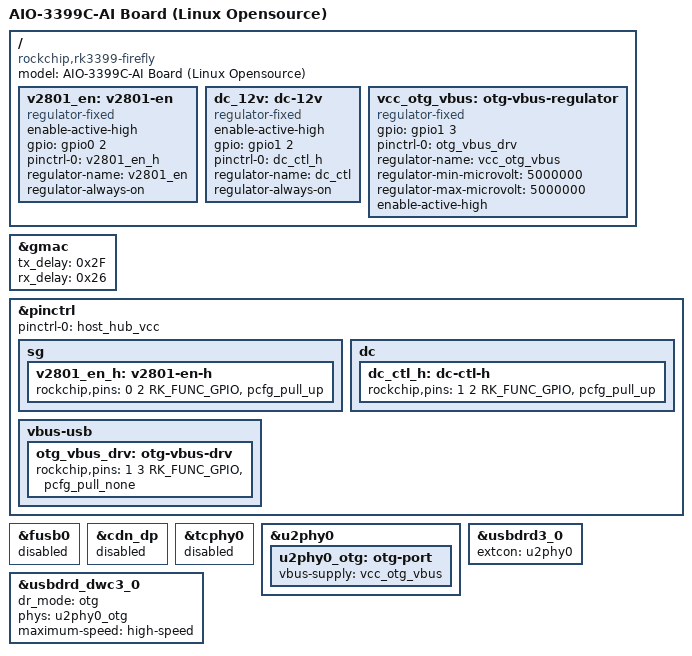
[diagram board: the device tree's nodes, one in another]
/*
 * Copyright (c) 2016 Fuzhou Rockchip Electronics Co., Ltd
 *
 * This file is dual-licensed: you can use it either under the terms
 * of the GPL or the X11 license, at your option. Note that this dual
 * licensing only applies to this file, and not this project as a
 * whole.
 *
 *  a) This file is free software; you can redistribute it and/or
 *     modify it under the terms of the GNU General Public License as
 *     published by the Free Software Foundation; either version 2 of the
 *     License, or (at your option) any later version.
 *
 *     This file is distributed in the hope that it will be useful,
 *     but WITHOUT ANY WARRANTY; without even the implied warranty of
 *     MERCHANTABILITY or FITNESS FOR A PARTICULAR PURPOSE.  See the
 *     GNU General Public License for more details.
 *
 * Or, alternatively,
 *     restriction, including without limitation the rights to use,
 *     copy, modify, merge, publish, distribute, sublicense, and/or
 *     sell copies of the Software, and to permit persons to whom the
 *     Software is furnished to do so, subject to the following
 *     conditions:
 *
 *     The above copyright notice and this permission notice shall be
 *     included in all copies or substantial portions of the Software.
 *
 *     THE SOFTWARE IS PROVIDED "AS IS", WITHOUT WARRANTY OF ANY KIND,
 *     EXPRESS OR IMPLIED, INCLUDING BUT NOT LIMITED TO THE WARRANTIES
 *     OF MERCHANTABILITY, FITNESS FOR A PARTICULAR PURPOSE AND
 *     NONINFRINGEMENT. IN NO EVENT SHALL THE AUTHORS OR COPYRIGHT
 *     HOLDERS BE LIABLE FOR ANY CLAIM, DAMAGES OR OTHER LIABILITY,
 *     WHETHER IN AN ACTION OF CONTRACT, TORT OR OTHERWISE, ARISING
 *     FROM, OUT OF OR IN CONNECTION WITH THE SOFTWARE OR THE USE OR
 *     OTHER DEALINGS IN THE SOFTWARE.
 */

/dts-v1/;

#include "rk3399-firefly-aioc.dtsi"

/ {
	model = "AIO-3399C-AI Board (Linux Opensource)";
	compatible = "rockchip,rk3399-firefly", "rockchip,rk3399";

	v2801_en: v2801-en {
		compatible = "regulator-fixed";
		enable-active-high;
		gpio = <&gpio0 2 GPIO_ACTIVE_HIGH>;
		pinctrl-names = "default";
		pinctrl-0 = <&v2801_en_h>;
		regulator-name = "v2801_en";
		regulator-always-on;
	};

	dc_12v: dc-12v {
		compatible = "regulator-fixed";
		enable-active-high;
		gpio = <&gpio1 2 GPIO_ACTIVE_HIGH>;
		pinctrl-names = "default";
		pinctrl-0 = <&dc_ctl_h>;
		regulator-name = "dc_ctl";
		regulator-always-on;
	};

	vcc_otg_vbus: otg-vbus-regulator {
		compatible = "regulator-fixed";
		gpio = <&gpio1 3 GPIO_ACTIVE_HIGH>;
		pinctrl-names = "default";
		pinctrl-0 = <&otg_vbus_drv>;
		regulator-name = "vcc_otg_vbus";
		regulator-min-microvolt = <5000000>;
		regulator-max-microvolt = <5000000>;
		enable-active-high;
	};
};

&gmac {
	tx_delay = <0x2F>;
	rx_delay = <0x26>;
};

&pinctrl {
	pinctrl-names = "default";
	pinctrl-0 = <&host_hub_vcc>;

	sg {
		v2801_en_h: v2801-en-h {
			rockchip,pins =
				<0 2 RK_FUNC_GPIO &pcfg_pull_up>;
		};
	};

	dc {
		dc_ctl_h: dc-ctl-h {
			rockchip,pins =
				<1 2 RK_FUNC_GPIO &pcfg_pull_up>;
		};
	};

	vbus-usb {
		otg_vbus_drv: otg-vbus-drv {
			rockchip,pins = <1 3 RK_FUNC_GPIO &pcfg_pull_none>;
		};
	};

};

&fusb0 {
    status = "disabled";
};

&cdn_dp {
    status = "disabled";
};

&tcphy0 {
    /delete-property/ extcon;
    status = "disabled";
};

&u2phy0 {
    status = "okay";
    /delete-property/ extcon;
    u2phy0_otg: otg-port {
        vbus-supply = <&vcc_otg_vbus>; /*配置Vbus regulator属性 */
	status = "okay";
    };
};

&usbdrd3_0 {
    status = "okay";
    extcon = <&u2phy0>;
};

&usbdrd_dwc3_0 {
    dr_mode = "otg";
    phys = <&u2phy0_otg>;
    maximum-speed = "high-speed";
    phy-names = "usb2-phy";
};

